# AT90PWM3 device description
Architecture: AVR8; Family: megaAVR
Programming and debug interfaces: ISP, HVPP, debugWIRE
Registers are 8-bit, access not given, no defined reset value unless marked. A register's access mark holds for its fields unless they carry their own. Offsets are from the block's base; lines under a group give offsets from that group; [hi:lo] are bit positions; {n}, {i} and the like mark numbered series; 'fields as' and 'values as' point back to an identical list; <NAME> marks a mode.

## Ordering variants
AT90PWM3-16SQ: SOIC32, up to 16 MHz, -40 to 105 C, 2.7 to 5.5 V
AT90PWM3-16MQT, AT90PWM3-16MQ: QFN32, up to 16 MHz, -40 to 105 C, 2.7 to 5.5 V

## Memory
prog space: start 0x0000 size 0x2000, little endian
  0x0000 FLASH size 0x2000 flash, rw, executable, page 0x40
  0x1f00 BOOT_SECTION_1 size 0x0100 flash, rw, executable, page 0x40
  0x1e00 BOOT_SECTION_2 size 0x0200 flash, rw, executable, page 0x40
  0x1c00 BOOT_SECTION_3 size 0x0400 flash, rw, executable, page 0x40
  0x1800 BOOT_SECTION_4 size 0x0800 flash, rw, executable, page 0x40
signatures space: start 0 size 3, little endian
  0 SIGNATURES size 3 signatures, ro
fuses space: start 0 size 0x0003, little endian
  0 FUSES size 0x0003 fuses, rw
lockbits space: start 0 size 0x0001, little endian
  0 LOCKBITS size 0x0001 lockbits, rw
data space: start 0x0000 size 0x0300, little endian
  0x0000 REGISTERS size 0x0020 regs
  0x0020 MAPPED_IO size 0x00e0 io
  0x0100 IRAM size 0x0200 ram
eeprom space: start 0x0000 size 0x0200, little endian
  0x0000 EEPROM size 0x0200 eeprom, rw, page 0x04
io space: start 0x00 size 0x40, little endian
osccal space: start 0 size 1, little endian
  0 OSCCAL size 1 osccal, ro

## Peripheral instances (address, pins/pin function, parameters)
PORTB at 0x00 — I/O Port
PORTC at 0x00 — I/O Port
PORTD at 0x00 — I/O Port
PORTE at 0x00 — I/O Port
BOOT_LOAD at 0x00 — Bootloader
EUSART at 0x00 — Extended USART
AC at 0x00 — Analog Comparator
DAC at 0x00 — Digital-to-Analog Converter
CPU at 0x00 — CPU Registers
  parameters: CORE_VERSION=V2E
TC0 at 0x00 — Timer/Counter, 8-bit
TC1 at 0x00 — Timer/Counter, 16-bit
ADC at 0x00 — Analog-to-Digital Converter
USART at 0x00
SPI at 0x00 — Serial Peripheral Interface
WDT at 0x00 — Watchdog Timer
EXINT at 0x00 — External Interrupts
EEPROM at 0x00
PSC{n} at 0x00 (n=0..2) — Power Stage Controller
FUSE at 0 in fuses — Fuses
LOCKBIT at 0 in lockbits — Lockbits

## Interrupts
0 RESET — External Pin, Power-on Reset, Brown-out Reset, Watchdog Reset and JTAG AVR Reset
1 PSC2_CAPT — PSC2 Capture Event
2 PSC2_EC — PSC2 End Cycle
3 PSC1_CAPT — PSC1 Capture Event
4 PSC1_EC — PSC1 End Cycle
5 PSC0_CAPT — PSC0 Capture Event
6 PSC0_EC — PSC0 End Cycle
7 ANALOG_COMP_0 — Analog Comparator 0
8 ANALOG_COMP_1 — Analog Comparator 1
9 ANALOG_COMP_2 — Analog Comparator 2
10 INT0 — External Interrupt Request 0
11 TIMER1_CAPT — Timer/Counter1 Capture Event
12 TIMER1_COMPA — Timer/Counter1 Compare Match A
13 TIMER1_COMPB — Timer/Counter Compare Match B
14 RESERVED15
15 TIMER1_OVF — Timer/Counter1 Overflow
16 TIMER0_COMPA — Timer/Counter0 Compare Match A
17 TIMER0_OVF — Timer/Counter0 Overflow
18 ADC — ADC Conversion Complete
19 INT1 — External Interrupt Request 1
20 SPI_STC — SPI Serial Transfer Complete
21 USART_RX — USART, Rx Complete
22 USART_UDRE — USART Data Register Empty
23 USART_TX — USART, Tx Complete
24 INT2 — External Interrupt Request 2
25 WDT — Watchdog Timeout Interrupt
26 EE_READY — EEPROM Ready
27 TIMER0_COMPB — Timer Counter 0 Compare Match B
28 INT3 — External Interrupt Request 3
29 RESERVED30
30 RESERVED31
31 SPM_READY — Store Program Memory Read

## Properties
SIGNATURES: JTAGID=0x9381, SIGNATURE0=0x1e, SIGNATURE1=0x93, SIGNATURE2=0x81
OCD: OCD_REVISION=1, OCD_DATAREG=0x31, PROGBASE=0x0000

## LOCKBIT — Lockbits
Instances: LOCKBIT 0 in lockbits
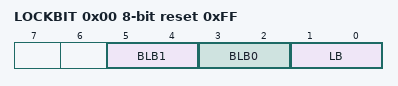
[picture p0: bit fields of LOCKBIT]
0x00 LOCKBIT reset 0xFF
  [5:4] BLB1 — Boot Loader Protection Mode
    0=LPM_SPM_DISABLE (LPM and SPM prohibited in Boot Section); 1=LPM_DISABLE (LPM prohibited in Boot Section); 2=SPM_DISABLE (SPM prohibited in Boot Section); 3=NO_LOCK (No lock on SPM and LPM in Boot Section)
  [3:2] BLB0 — Boot Loader Protection Mode
    0=LPM_SPM_DISABLE (LPM and SPM prohibited in Application Section); 1=LPM_DISABLE (LPM prohibited in Application Section); 2=SPM_DISABLE (SPM prohibited in Application Section); 3=NO_LOCK (No lock on SPM and LPM in Application Section)
  [1:0] LB — Memory Lock
    0=PROG_VER_DISABLED (Further programming and verification disabled); 2=PROG_DISABLED (Further programming disabled); 3=NO_LOCK (No memory lock features enabled)
